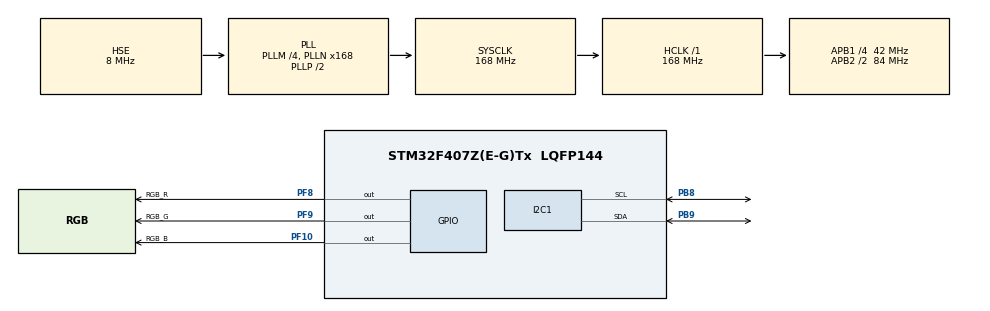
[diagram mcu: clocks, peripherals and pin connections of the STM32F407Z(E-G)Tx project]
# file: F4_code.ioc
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FREERTOS.INCLUDE_eTaskGetState=1
FREERTOS.INCLUDE_pcTaskGetTaskName=1
FREERTOS.INCLUDE_uxTaskGetStackHighWaterMark=1
FREERTOS.INCLUDE_vTaskCleanUpResources=1
FREERTOS.INCLUDE_vTaskDelayUntil=1
FREERTOS.INCLUDE_xEventGroupSetBitFromISR=1
FREERTOS.INCLUDE_xQueueGetMutexHolder=1
FREERTOS.INCLUDE_xSemaphoreGetMutexHolder=1
FREERTOS.INCLUDE_xTaskAbortDelay=1
FREERTOS.INCLUDE_xTaskGetCurrentTaskHandle=1
FREERTOS.INCLUDE_xTaskGetHandle=1
FREERTOS.INCLUDE_xTimerPendFunctionCall=1
FREERTOS.Tasks01=test,0,128,test_tack,Default,NULL,Dynamic,NULL,NULL
FREERTOS.configUSE_TIMERS=1
I2C1.I2C_Mode=I2C_Standard
Mcu.Family=STM32F4
Mcu.Name=STM32F407Z(E-G)Tx
Mcu.Package=LQFP144
NVIC.PriorityGroup=NVIC_PRIORITYGROUP_4
PA13.Mode=Serial_Wire
PA13.Signal=SYS_JTMS-SWDIO
PA14.Mode=Serial_Wire
PA14.Signal=SYS_JTCK-SWCLK
PB8.Mode=I2C
PB8.Signal=I2C1_SCL
PB9.Mode=I2C
PB9.Signal=I2C1_SDA
PF10.GPIO_Label=RGB_B
PF10.GPIO_Speed=GPIO_SPEED_FREQ_HIGH
PF10.PinState=GPIO_PIN_SET
PF10.Signal=GPIO_Output
PF8.GPIO_Label=RGB_R
PF8.GPIO_Speed=GPIO_SPEED_FREQ_HIGH
PF8.PinState=GPIO_PIN_SET
PF8.Signal=GPIO_Output
PF9.GPIO_Label=RGB_G
PF9.GPIO_Speed=GPIO_SPEED_FREQ_HIGH
PF9.PinState=GPIO_PIN_SET
PF9.Signal=GPIO_Output
PH0-OSC_IN.Mode=HSE-External-Oscillator
PH0-OSC_IN.Signal=RCC_OSC_IN
PH1-OSC_OUT.Mode=HSE-External-Oscillator
PH1-OSC_OUT.Signal=RCC_OSC_OUT
ProjectManager.HeapSize=0x200
ProjectManager.StackSize=0x400
ProjectManager.TargetToolchain=MDK-ARM V5.32
RCC.48MHZClocksFreq_Value=84000000
RCC.AHBFreq_Value=168000000
RCC.APB1CLKDivider=RCC_HCLK_DIV4
RCC.APB1Freq_Value=42000000
RCC.APB1TimFreq_Value=84000000
RCC.APB2CLKDivider=RCC_HCLK_DIV2
RCC.APB2Freq_Value=84000000
RCC.APB2TimFreq_Value=168000000
RCC.CortexFreq_Value=168000000
RCC.HCLKFreq_Value=168000000
RCC.HSE_VALUE=8000000
RCC.HSI_VALUE=16000000
RCC.LSE_VALUE=32768
RCC.PLLM=4
RCC.PLLN=168
RCC.PLLSourceVirtual=RCC_PLLSOURCE_HSE
RCC.SYSCLKFreq_VALUE=168000000
RCC.SYSCLKSource=RCC_SYSCLKSOURCE_PLLCLK
RCC.VCOOutputFreq_Value=336000000
VP_FREERTOS_VS_CMSIS_V1.Mode=CMSIS_V1
board=custom

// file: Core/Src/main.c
/* USER CODE BEGIN Header */
/**
 ******************************************************************************
 * @file           : main.c
 * @brief          : Main program body
 ******************************************************************************
 * @attention
 *
 * Copyright (c) 2023 STMicroelectronics.
 * All rights reserved.
 *
 * This software is licensed under terms that can be found in the LICENSE file
 * in the root directory of this software component.
 * If no LICENSE file comes with this software, it is provided AS-IS.
 *
 ******************************************************************************
 */
/* USER CODE END Header */
#include "main.h"
#include "cmsis_os.h"
#include "i2c.h"
#include "gpio.h"

/* USER CODE BEGIN Includes */
#include "user.h"
/* USER CODE END Includes */

void SystemClock_Config(void);
void MX_FREERTOS_Init(void);

int main(void)
{

  /* MCU Configuration--------------------------------------------------------*/

  /* Reset of all peripherals, Initializes the Flash interface and the Systick. */
  HAL_Init();

  /* Configure the system clock */
  SystemClock_Config();

  /* Initialize all configured peripherals */
  MX_GPIO_Init();
  MX_I2C1_Init();
  /* USER CODE BEGIN 2 */
  control_init();
  /* USER CODE END 2 */

  /* Call init function for freertos objects (in freertos.c) */
  MX_FREERTOS_Init();

  /* Start scheduler */
  osKernelStart();
  /* We should never get here as control is now taken by the scheduler */
  /* Infinite loop */
  while (1)
  {

  }
}

void SystemClock_Config(void)
{
  RCC_OscInitTypeDef RCC_OscInitStruct = {0};
  RCC_ClkInitTypeDef RCC_ClkInitStruct = {0};

  /** Configure the main internal regulator output voltage
   */
  __HAL_RCC_PWR_CLK_ENABLE();
  __HAL_PWR_VOLTAGESCALING_CONFIG(PWR_REGULATOR_VOLTAGE_SCALE1);

  /** Initializes the RCC Oscillators according to the specified parameters
   * in the RCC_OscInitTypeDef structure.
   */
  RCC_OscInitStruct.OscillatorType = RCC_OSCILLATORTYPE_HSE;
  RCC_OscInitStruct.HSEState = RCC_HSE_ON;
  RCC_OscInitStruct.PLL.PLLState = RCC_PLL_ON;
  RCC_OscInitStruct.PLL.PLLSource = RCC_PLLSOURCE_HSE;
  RCC_OscInitStruct.PLL.PLLM = 4;
  RCC_OscInitStruct.PLL.PLLN = 168;
  RCC_OscInitStruct.PLL.PLLP = RCC_PLLP_DIV2;
  RCC_OscInitStruct.PLL.PLLQ = 4;
  if (HAL_RCC_OscConfig(&RCC_OscInitStruct) != HAL_OK)
  {
    Error_Handler();
  }

  /** Initializes the CPU, AHB and APB buses clocks
   */
  RCC_ClkInitStruct.ClockType = RCC_CLOCKTYPE_HCLK | RCC_CLOCKTYPE_SYSCLK | RCC_CLOCKTYPE_PCLK1 | RCC_CLOCKTYPE_PCLK2;
  RCC_ClkInitStruct.SYSCLKSource = RCC_SYSCLKSOURCE_PLLCLK;
  RCC_ClkInitStruct.AHBCLKDivider = RCC_SYSCLK_DIV1;
  RCC_ClkInitStruct.APB1CLKDivider = RCC_HCLK_DIV4;
  RCC_ClkInitStruct.APB2CLKDivider = RCC_HCLK_DIV2;

  if (HAL_RCC_ClockConfig(&RCC_ClkInitStruct, FLASH_LATENCY_5) != HAL_OK)
  {
    Error_Handler();
  }
}

void Error_Handler(void)
{
  __disable_irq();
  while (1)
  {
  }
}

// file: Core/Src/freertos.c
/* USER CODE BEGIN Header */
/**
 ******************************************************************************
 * File Name          : freertos.c
 * Description        : Code for freertos applications
 ******************************************************************************
 * @attention
 *
 * Copyright (c) 2023 STMicroelectronics.
 * All rights reserved.
 *
 * This software is licensed under terms that can be found in the LICENSE file
 * in the root directory of this software component.
 * If no LICENSE file comes with this software, it is provided AS-IS.
 *
 ******************************************************************************
 */
/* USER CODE END Header */

#include "FreeRTOS.h"
#include "task.h"
#include "main.h"
#include "cmsis_os.h"

/* USER CODE BEGIN Includes */
#include "user.h"
/* USER CODE END Includes */

/* USER CODE BEGIN Variables */
osThreadId oled_Refresh_Handle;
osThreadId oled_show_Handle;
/* USER CODE END Variables */
osThreadId testHandle;

void test_tack(void const *argument);

void MX_FREERTOS_Init(void); /* (MISRA C 2004 rule 8.1) */

/* GetIdleTaskMemory prototype (linked to static allocation support) */
void vApplicationGetIdleTaskMemory(StaticTask_t **ppxIdleTaskTCBBuffer, StackType_t **ppxIdleTaskStackBuffer, uint32_t *pulIdleTaskStackSize);

/* GetTimerTaskMemory prototype (linked to static allocation support) */
void vApplicationGetTimerTaskMemory(StaticTask_t **ppxTimerTaskTCBBuffer, StackType_t **ppxTimerTaskStackBuffer, uint32_t *pulTimerTaskStackSize);

/* USER CODE BEGIN GET_IDLE_TASK_MEMORY */
static StaticTask_t xIdleTaskTCBBuffer;
static StackType_t xIdleStack[configMINIMAL_STACK_SIZE];

void vApplicationGetIdleTaskMemory(StaticTask_t **ppxIdleTaskTCBBuffer, StackType_t **ppxIdleTaskStackBuffer, uint32_t *pulIdleTaskStackSize)
{
  *ppxIdleTaskTCBBuffer = &xIdleTaskTCBBuffer;
  *ppxIdleTaskStackBuffer = &xIdleStack[0];
  *pulIdleTaskStackSize = configMINIMAL_STACK_SIZE;
  /* place for user code */
}
/* USER CODE END GET_IDLE_TASK_MEMORY */

/* USER CODE BEGIN GET_TIMER_TASK_MEMORY */
static StaticTask_t xTimerTaskTCBBuffer;
static StackType_t xTimerStack[configTIMER_TASK_STACK_DEPTH];

void vApplicationGetTimerTaskMemory(StaticTask_t **ppxTimerTaskTCBBuffer, StackType_t **ppxTimerTaskStackBuffer, uint32_t *pulTimerTaskStackSize)
{
  *ppxTimerTaskTCBBuffer = &xTimerTaskTCBBuffer;
  *ppxTimerTaskStackBuffer = &xTimerStack[0];
  *pulTimerTaskStackSize = configTIMER_TASK_STACK_DEPTH;
  /* place for user code */
}
/* USER CODE END GET_TIMER_TASK_MEMORY */

void MX_FREERTOS_Init(void)
{

  /* Create the thread(s) */
  /* definition and creation of test */
  osThreadDef(test, test_tack, osPriorityNormal, 0, 128);
  testHandle = osThreadCreate(osThread(test), NULL);

  /* USER CODE BEGIN RTOS_THREADS */
  /* add threads, ... */
  osThreadDef(Oled_Refresh, Oled_Refresh_tack, osPriorityNormal, 1, 128);
  oled_Refresh_Handle = osThreadCreate(osThread(Oled_Refresh), NULL);
  osThreadDef(Oled_show, Oled_show_tack, osPriorityNormal, 2, 2048);
  oled_show_Handle = osThreadCreate(osThread(Oled_show), NULL);

  /* USER CODE END RTOS_THREADS */
}

void test_tack(void const *argument)
{
  /* USER CODE BEGIN test_tack */
  /* Infinite loop */
  while (1)
  {
    osDelay(500);
    HAL_GPIO_TogglePin(RGB_B_GPIO_Port, RGB_B_Pin);
  }
  /* USER CODE END test_tack */
}
